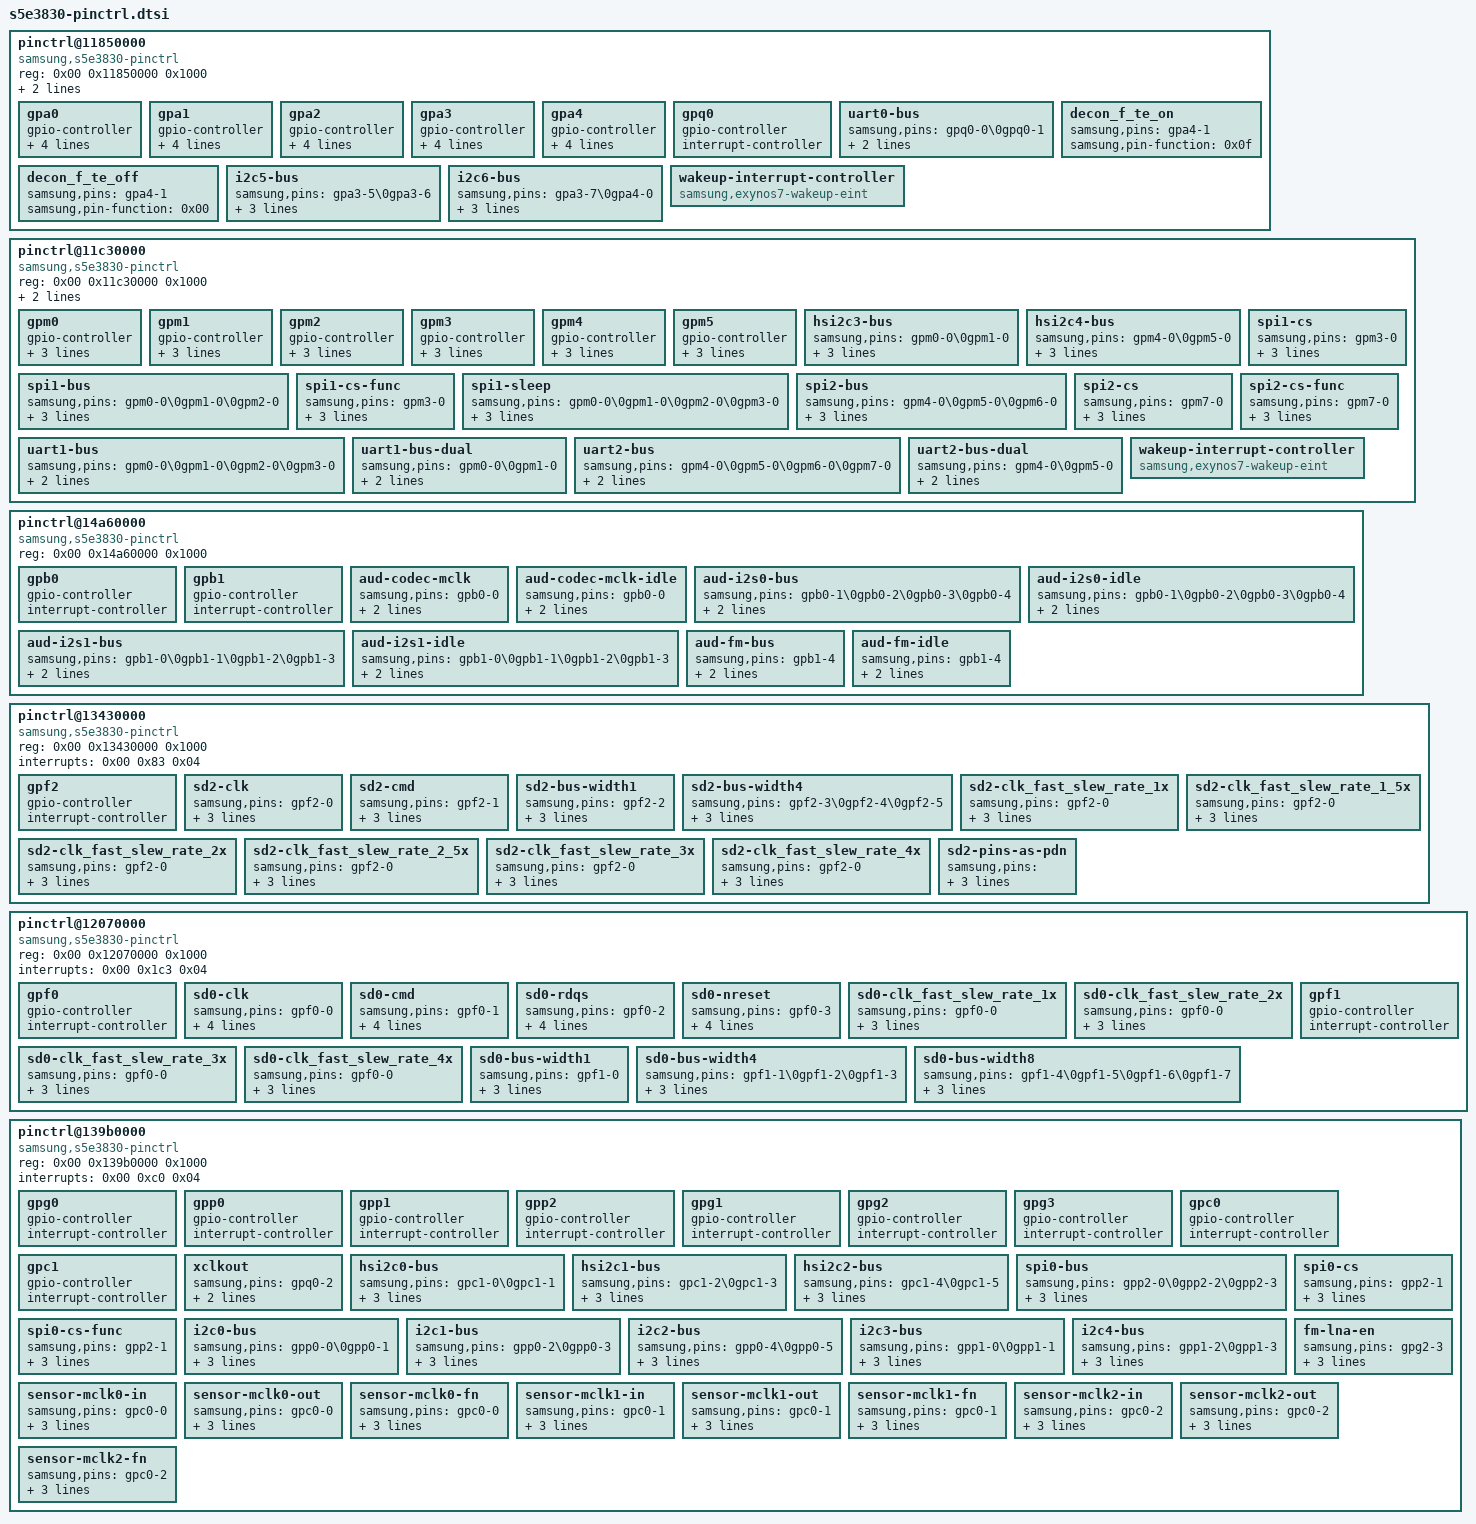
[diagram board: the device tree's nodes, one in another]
/* Samsung Exynos 850 (S5E3830) - pin controllers and board pin config */

	pinctrl@11850000 {
		compatible = "samsung,s5e3830-pinctrl";
		reg = <0x00 0x11850000 0x1000>;
		interrupts = <0x00 0x01 0x04 0x00 0x02 0x04 0x00 0x03 0x04 0x00 0x04 0x04 0x00 0x05 0x04 0x00 0x06 0x04 0x00 0x07 0x04 0x00 0x08 0x04 0x00 0x09 0x04 0x00 0x0a 0x04 0x00 0x0b 0x04 0x00 0x0c 0x04 0x00 0x0d 0x04 0x00 0x0e 0x04 0x00 0x0f 0x04 0x00 0x10 0x04 0x00 0x11 0x04 0x00 0x12 0x04 0x00 0x13 0x04 0x00 0x14 0x04 0x00 0x15 0x04 0x00 0x16 0x04 0x00 0x17 0x04 0x00 0x18 0x04 0x00 0x19 0x04 0x00 0x1a 0x04 0x00 0x1b 0x04 0x00 0x1c 0x04 0x00 0x1d 0x04 0x00 0x1e 0x04 0x00 0x1f 0x04 0x00 0x20 0x04>;
		phandle = <0xb8>;

		gpa0 {
			gpio-controller;
			#gpio-cells = <0x02>;
			interrupt-controller;
			#interrupt-cells = <0x03>;
			interrupt-parent = <0x01>;
			interrupts = <0x00 0x01 0x04 0x00 0x02 0x04 0x00 0x03 0x04 0x00 0x04 0x04 0x00 0x05 0x04 0x00 0x06 0x04 0x00 0x07 0x04 0x00 0x08 0x04>;
			phandle = <0xb9>;
		};

		gpa1 {
			gpio-controller;
			#gpio-cells = <0x02>;
			interrupt-controller;
			#interrupt-cells = <0x03>;
			interrupt-parent = <0x01>;
			interrupts = <0x00 0x09 0x04 0x00 0x0a 0x04 0x00 0x0b 0x04 0x00 0x0c 0x04 0x00 0x0d 0x04 0x00 0x0e 0x04 0x00 0x0f 0x04 0x00 0x10 0x04>;
			phandle = <0xba>;
		};

		gpa2 {
			gpio-controller;
			#gpio-cells = <0x02>;
			interrupt-controller;
			#interrupt-cells = <0x03>;
			interrupt-parent = <0x01>;
			interrupts = <0x00 0x11 0x04 0x00 0x12 0x04 0x00 0x13 0x04 0x00 0x14 0x04 0x00 0x15 0x04 0x00 0x16 0x04 0x00 0x17 0x04 0x00 0x18 0x04>;
			phandle = <0xbb>;
		};

		gpa3 {
			gpio-controller;
			#gpio-cells = <0x02>;
			interrupt-controller;
			#interrupt-cells = <0x03>;
			interrupt-parent = <0x01>;
			interrupts = <0x00 0x19 0x04 0x00 0x1a 0x04 0x00 0x1b 0x04 0x00 0x1c 0x04 0x00 0x1d 0x04 0x00 0x1e 0x04 0x00 0x1f 0x04 0x00 0x20 0x04>;
			phandle = <0x1b>;
		};

		gpa4 {
			gpio-controller;
			#gpio-cells = <0x02>;
			interrupt-controller;
			#interrupt-cells = <0x03>;
			interrupt-parent = <0x01>;
			interrupts = <0x00 0x21 0x04 0x00 0x22 0x04 0x00 0x23 0x04 0x00 0x24 0x04>;
			phandle = <0x1d>;
		};

		gpq0 {
			gpio-controller;
			#gpio-cells = <0x02>;
			interrupt-controller;
			#interrupt-cells = <0x02>;
			phandle = <0xbc>;
		};

		uart0-bus {
			samsung,pins = "gpq0-0\0gpq0-1";
			samsung,pin-function = <0x02>;
			samsung,pin-pud = <0x03>;
			phandle = <0x11>;
		};

		decon_f_te_on {
			samsung,pins = "gpa4-1";
			samsung,pin-function = <0x0f>;
			phandle = <0x73>;
		};

		decon_f_te_off {
			samsung,pins = "gpa4-1";
			samsung,pin-function = <0x00>;
			phandle = <0x74>;
		};

		i2c5-bus {
			samsung,pins = "gpa3-5\0gpa3-6";
			samsung,pin-function = <0x03>;
			samsung,pin-pud = <0x03>;
			samsung,pin-drv = <0x00>;
			phandle = <0x1a>;
		};

		i2c6-bus {
			samsung,pins = "gpa3-7\0gpa4-0";
			samsung,pin-function = <0x03>;
			samsung,pin-pud = <0x03>;
			samsung,pin-drv = <0x00>;
			phandle = <0x1c>;
		};

		wakeup-interrupt-controller {
			compatible = "samsung,exynos7-wakeup-eint";
		};
	};

	pinctrl@11c30000 {
		compatible = "samsung,s5e3830-pinctrl";
		reg = <0x00 0x11c30000 0x1000>;
		interrupts = <0x00 0x27 0x04 0x00 0x28 0x04 0x00 0x29 0x04 0x00 0x2a 0x04 0x00 0x2b 0x04 0x00 0x2c 0x04 0x00 0x2d 0x04 0x00 0x2e 0x04>;
		phandle = <0xbd>;

		gpm0 {
			gpio-controller;
			#gpio-cells = <0x02>;
			interrupt-controller;
			#interrupt-cells = <0x03>;
			interrupt-parent = <0x01>;
			interrupts = <0x00 0x27 0x04>;
			phandle = <0x08>;
		};

		gpm1 {
			gpio-controller;
			#gpio-cells = <0x02>;
			interrupt-controller;
			#interrupt-cells = <0x03>;
			interrupt-parent = <0x01>;
			interrupts = <0x00 0x28 0x04>;
			phandle = <0x09>;
		};

		gpm2 {
			gpio-controller;
			#gpio-cells = <0x02>;
			interrupt-controller;
			#interrupt-cells = <0x03>;
			interrupt-parent = <0x01>;
			interrupts = <0x00 0x29 0x04>;
			phandle = <0xbe>;
		};

		gpm3 {
			gpio-controller;
			#gpio-cells = <0x02>;
			interrupt-controller;
			#interrupt-cells = <0x03>;
			interrupt-parent = <0x01>;
			interrupts = <0x00 0x2a 0x04>;
			phandle = <0xbf>;
		};

		gpm4 {
			gpio-controller;
			#gpio-cells = <0x02>;
			interrupt-controller;
			#interrupt-cells = <0x03>;
			interrupt-parent = <0x01>;
			interrupts = <0x00 0x2b 0x04>;
			phandle = <0x0b>;
		};

		gpm5 {
			gpio-controller;
			#gpio-cells = <0x02>;
			interrupt-controller;
			#interrupt-cells = <0x03>;
			interrupt-parent = <0x01>;
			interrupts = <0x00 0x2c 0x04>;
			phandle = <0x0c>;
		};

		hsi2c3-bus {
			samsung,pins = "gpm0-0\0gpm1-0";
			samsung,pin-function = <0x02>;
			samsung,pin-pud = <0x03>;
			samsung,pin-drv = <0x00>;
			phandle = <0x07>;
		};

		hsi2c4-bus {
			samsung,pins = "gpm4-0\0gpm5-0";
			samsung,pin-function = <0x02>;
			samsung,pin-pud = <0x03>;
			samsung,pin-drv = <0x00>;
			phandle = <0x0a>;
		};

		spi1-bus {
			samsung,pins = "gpm0-0\0gpm1-0\0gpm2-0";
			samsung,pin-function = <0x02>;
			samsung,pin-pud = <0x00>;
			samsung,pin-drv = <0x00>;
			phandle = <0x0f>;
		};

		spi1-cs {
			samsung,pins = "gpm3-0";
			samsung,pin-function = <0x01>;
			samsung,pin-pud = <0x00>;
			samsung,pin-drv = <0x00>;
			phandle = <0xc0>;
		};

		spi1-cs-func {
			samsung,pins = "gpm3-0";
			samsung,pin-function = <0x02>;
			samsung,pin-pud = <0x00>;
			samsung,pin-drv = <0x00>;
			phandle = <0xc1>;
		};

		spi1-sleep {
			samsung,pins = "gpm0-0\0gpm1-0\0gpm2-0\0gpm3-0";
			samsung,pin-function = <0x00>;
			samsung,pin-pud = <0x01>;
			samsung,pin-drv = <0x00>;
			phandle = <0xc2>;
		};

		spi2-bus {
			samsung,pins = "gpm4-0\0gpm5-0\0gpm6-0";
			samsung,pin-function = <0x02>;
			samsung,pin-pud = <0x00>;
			samsung,pin-drv = <0x00>;
			phandle = <0x10>;
		};

		spi2-cs {
			samsung,pins = "gpm7-0";
			samsung,pin-function = <0x01>;
			samsung,pin-pud = <0x00>;
			samsung,pin-drv = <0x00>;
			phandle = <0xc3>;
		};

		spi2-cs-func {
			samsung,pins = "gpm7-0";
			samsung,pin-function = <0x02>;
			samsung,pin-pud = <0x00>;
			samsung,pin-drv = <0x00>;
			phandle = <0xc4>;
		};

		uart1-bus {
			samsung,pins = "gpm0-0\0gpm1-0\0gpm2-0\0gpm3-0";
			samsung,pin-function = <0x02>;
			samsung,pin-pud = <0x00>;
			phandle = <0xc5>;
		};

		uart1-bus-dual {
			samsung,pins = "gpm0-0\0gpm1-0";
			samsung,pin-function = <0x02>;
			samsung,pin-pud = <0x00>;
			phandle = <0xc6>;
		};

		uart2-bus {
			samsung,pins = "gpm4-0\0gpm5-0\0gpm6-0\0gpm7-0";
			samsung,pin-function = <0x02>;
			samsung,pin-pud = <0x00>;
			phandle = <0xc7>;
		};

		uart2-bus-dual {
			samsung,pins = "gpm4-0\0gpm5-0";
			samsung,pin-function = <0x02>;
			samsung,pin-pud = <0x00>;
			phandle = <0xc8>;
		};

		wakeup-interrupt-controller {
			compatible = "samsung,exynos7-wakeup-eint";
		};
	};

	pinctrl@14a60000 {
		compatible = "samsung,s5e3830-pinctrl";
		reg = <0x00 0x14a60000 0x1000>;
		phandle = <0xc9>;

		gpb0 {
			gpio-controller;
			#gpio-cells = <0x02>;
			interrupt-controller;
			#interrupt-cells = <0x02>;
			phandle = <0xca>;
		};

		gpb1 {
			gpio-controller;
			#gpio-cells = <0x02>;
			interrupt-controller;
			#interrupt-cells = <0x02>;
			phandle = <0xcb>;
		};

		aud-codec-mclk {
			samsung,pins = "gpb0-0";
			samsung,pin-function = <0x02>;
			samsung,pin-pud = <0x01>;
			phandle = <0x7d>;
		};

		aud-codec-mclk-idle {
			samsung,pins = "gpb0-0";
			samsung,pin-function = <0x00>;
			samsung,pin-pud = <0x01>;
			phandle = <0x7f>;
		};

		aud-i2s0-bus {
			samsung,pins = "gpb0-1\0gpb0-2\0gpb0-3\0gpb0-4";
			samsung,pin-function = <0x02>;
			samsung,pin-pud = <0x01>;
			phandle = <0x7c>;
		};

		aud-i2s0-idle {
			samsung,pins = "gpb0-1\0gpb0-2\0gpb0-3\0gpb0-4";
			samsung,pin-function = <0x00>;
			samsung,pin-pud = <0x01>;
			phandle = <0x7e>;
		};

		aud-i2s1-bus {
			samsung,pins = "gpb1-0\0gpb1-1\0gpb1-2\0gpb1-3";
			samsung,pin-function = <0x02>;
			samsung,pin-pud = <0x01>;
			phandle = <0x80>;
		};

		aud-i2s1-idle {
			samsung,pins = "gpb1-0\0gpb1-1\0gpb1-2\0gpb1-3";
			samsung,pin-function = <0x00>;
			samsung,pin-pud = <0x01>;
			phandle = <0x81>;
		};

		aud-fm-bus {
			samsung,pins = "gpb1-4";
			samsung,pin-function = <0x02>;
			samsung,pin-pud = <0x01>;
			phandle = <0x97>;
		};

		aud-fm-idle {
			samsung,pins = "gpb1-4";
			samsung,pin-function = <0x00>;
			samsung,pin-pud = <0x01>;
			phandle = <0x98>;
		};
	};

	pinctrl@13430000 {
		compatible = "samsung,s5e3830-pinctrl";
		reg = <0x00 0x13430000 0x1000>;
		interrupts = <0x00 0x83 0x04>;
		phandle = <0xcc>;

		gpf2 {
			gpio-controller;
			#gpio-cells = <0x02>;
			interrupt-controller;
			#interrupt-cells = <0x02>;
			phandle = <0xcd>;
		};

		sd2-clk {
			samsung,pins = "gpf2-0";
			samsung,pin-function = <0x02>;
			samsung,pin-pud = <0x00>;
			samsung,pin-drv = <0x02>;
			phandle = <0x4a>;
		};

		sd2-cmd {
			samsung,pins = "gpf2-1";
			samsung,pin-function = <0x02>;
			samsung,pin-pud = <0x03>;
			samsung,pin-drv = <0x02>;
			phandle = <0x4b>;
		};

		sd2-bus-width1 {
			samsung,pins = "gpf2-2";
			samsung,pin-function = <0x02>;
			samsung,pin-pud = <0x03>;
			samsung,pin-drv = <0x02>;
			phandle = <0x4c>;
		};

		sd2-bus-width4 {
			samsung,pins = "gpf2-3\0gpf2-4\0gpf2-5";
			samsung,pin-function = <0x02>;
			samsung,pin-pud = <0x03>;
			samsung,pin-drv = <0x02>;
			phandle = <0x4d>;
		};

		sd2-clk_fast_slew_rate_1x {
			samsung,pins = "gpf2-0";
			samsung,pin-function = <0x02>;
			samsung,pin-pud = <0x00>;
			samsung,pin-drv = <0x00>;
			phandle = <0x43>;
		};

		sd2-clk_fast_slew_rate_1_5x {
			samsung,pins = "gpf2-0";
			samsung,pin-function = <0x02>;
			samsung,pin-pud = <0x00>;
			samsung,pin-drv = <0x01>;
			phandle = <0x44>;
		};

		sd2-clk_fast_slew_rate_2x {
			samsung,pins = "gpf2-0";
			samsung,pin-function = <0x02>;
			samsung,pin-pud = <0x00>;
			samsung,pin-drv = <0x02>;
			phandle = <0x45>;
		};

		sd2-clk_fast_slew_rate_2_5x {
			samsung,pins = "gpf2-0";
			samsung,pin-function = <0x02>;
			samsung,pin-pud = <0x00>;
			samsung,pin-drv = <0x03>;
			phandle = <0x46>;
		};

		sd2-clk_fast_slew_rate_3x {
			samsung,pins = "gpf2-0";
			samsung,pin-function = <0x02>;
			samsung,pin-pud = <0x00>;
			samsung,pin-drv = <0x04>;
			phandle = <0x47>;
		};

		sd2-clk_fast_slew_rate_4x {
			samsung,pins = "gpf2-0";
			samsung,pin-function = <0x02>;
			samsung,pin-pud = <0x00>;
			samsung,pin-drv = <0x05>;
			phandle = <0x48>;
		};

		sd2-pins-as-pdn {
			samsung,pins = "gpf2-0\0gpf2-1\0gpf2-2\0gpf2-3\0gpf2-4\0gpf2-5";
			samsung,pin-function = <0x00>;
			samsung,pin-pud = <0x02>;
			phandle = <0x49>;
		};
	};

	pinctrl@12070000 {
		compatible = "samsung,s5e3830-pinctrl";
		reg = <0x00 0x12070000 0x1000>;
		interrupts = <0x00 0x1c3 0x04>;
		phandle = <0xce>;

		gpf0 {
			gpio-controller;
			#gpio-cells = <0x02>;
			interrupt-controller;
			#interrupt-cells = <0x02>;
			phandle = <0xcf>;
		};

		sd0-clk {
			samsung,pins = "gpf0-0";
			samsung,pin-function = <0x02>;
			samsung,pin-pud = <0x00>;
			samsung,pin-drv = <0x03>;
			samsung,pin-pud-pdn = <0x00>;
			phandle = <0x37>;
		};

		sd0-cmd {
			samsung,pins = "gpf0-1";
			samsung,pin-function = <0x02>;
			samsung,pin-pud = <0x03>;
			samsung,pin-drv = <0x03>;
			samsung,pin-pud-pdn = <0x03>;
			phandle = <0x38>;
		};

		sd0-rdqs {
			samsung,pins = "gpf0-2";
			samsung,pin-function = <0x02>;
			samsung,pin-pud = <0x01>;
			samsung,pin-drv = <0x03>;
			samsung,pin-pud-pdn = <0x01>;
			phandle = <0x39>;
		};

		sd0-nreset {
			samsung,pins = "gpf0-3";
			samsung,pin-function = <0x02>;
			samsung,pin-pud = <0x03>;
			samsung,pin-drv = <0x03>;
			samsung,pin-pud-pdn = <0x03>;
			phandle = <0x3a>;
		};

		sd0-clk_fast_slew_rate_1x {
			samsung,pins = "gpf0-0";
			samsung,pin-function = <0x02>;
			samsung,pin-pud = <0x00>;
			samsung,pin-drv = <0x01>;
			phandle = <0x3e>;
		};

		sd0-clk_fast_slew_rate_2x {
			samsung,pins = "gpf0-0";
			samsung,pin-function = <0x02>;
			samsung,pin-pud = <0x00>;
			samsung,pin-drv = <0x02>;
			phandle = <0x3f>;
		};

		sd0-clk_fast_slew_rate_3x {
			samsung,pins = "gpf0-0";
			samsung,pin-function = <0x02>;
			samsung,pin-pud = <0x00>;
			samsung,pin-drv = <0x02>;
			phandle = <0x40>;
		};

		sd0-clk_fast_slew_rate_4x {
			samsung,pins = "gpf0-0";
			samsung,pin-function = <0x02>;
			samsung,pin-pud = <0x00>;
			samsung,pin-drv = <0x03>;
			phandle = <0x41>;
		};

		gpf1 {
			gpio-controller;
			#gpio-cells = <0x02>;
			interrupt-controller;
			#interrupt-cells = <0x02>;
			phandle = <0xd0>;
		};

		sd0-bus-width1 {
			samsung,pins = "gpf1-0";
			samsung,pin-function = <0x02>;
			samsung,pin-pud = <0x03>;
			samsung,pin-drv = <0x03>;
			phandle = <0x3b>;
		};

		sd0-bus-width4 {
			samsung,pins = "gpf1-1\0gpf1-2\0gpf1-3";
			samsung,pin-function = <0x02>;
			samsung,pin-pud = <0x03>;
			samsung,pin-drv = <0x03>;
			phandle = <0x3c>;
		};

		sd0-bus-width8 {
			samsung,pins = "gpf1-4\0gpf1-5\0gpf1-6\0gpf1-7";
			samsung,pin-function = <0x02>;
			samsung,pin-pud = <0x03>;
			samsung,pin-drv = <0x03>;
			phandle = <0x3d>;
		};
	};

	pinctrl@139b0000 {
		compatible = "samsung,s5e3830-pinctrl";
		reg = <0x00 0x139b0000 0x1000>;
		interrupts = <0x00 0xc0 0x04>;
		phandle = <0xd1>;

		gpg0 {
			gpio-controller;
			#gpio-cells = <0x02>;
			interrupt-controller;
			#interrupt-cells = <0x02>;
			phandle = <0xd2>;
		};

		gpp0 {
			gpio-controller;
			#gpio-cells = <0x02>;
			interrupt-controller;
			#interrupt-cells = <0x02>;
			phandle = <0x14>;
		};

		gpp1 {
			gpio-controller;
			#gpio-cells = <0x02>;
			interrupt-controller;
			#interrupt-cells = <0x02>;
			phandle = <0x18>;
		};

		gpp2 {
			gpio-controller;
			#gpio-cells = <0x02>;
			interrupt-controller;
			#interrupt-cells = <0x02>;
			phandle = <0xd3>;
		};

		gpg1 {
			gpio-controller;
			#gpio-cells = <0x02>;
			interrupt-controller;
			#interrupt-cells = <0x02>;
			phandle = <0xd4>;
		};

		gpg2 {
			gpio-controller;
			#gpio-cells = <0x02>;
			interrupt-controller;
			#interrupt-cells = <0x02>;
			phandle = <0x96>;
		};

		gpg3 {
			gpio-controller;
			#gpio-cells = <0x02>;
			interrupt-controller;
			#interrupt-cells = <0x02>;
			phandle = <0xd5>;
		};

		gpc0 {
			gpio-controller;
			#gpio-cells = <0x02>;
			interrupt-controller;
			#interrupt-cells = <0x02>;
			phandle = <0xd6>;
		};

		gpc1 {
			gpio-controller;
			#gpio-cells = <0x02>;
			interrupt-controller;
			#interrupt-cells = <0x02>;
			phandle = <0x04>;
		};

		xclkout {
			samsung,pins = "gpq0-2";
			samsung,pin-function = <0x02>;
			samsung,pin-pud = <0x00>;
			phandle = <0xd7>;
		};

		hsi2c0-bus {
			samsung,pins = "gpc1-0\0gpc1-1";
			samsung,pin-function = <0x02>;
			samsung,pin-pud = <0x03>;
			samsung,pin-drv = <0x00>;
			phandle = <0x02>;
		};

		hsi2c1-bus {
			samsung,pins = "gpc1-2\0gpc1-3";
			samsung,pin-function = <0x02>;
			samsung,pin-pud = <0x03>;
			samsung,pin-drv = <0x00>;
			phandle = <0x05>;
		};

		hsi2c2-bus {
			samsung,pins = "gpc1-4\0gpc1-5";
			samsung,pin-function = <0x02>;
			samsung,pin-pud = <0x03>;
			samsung,pin-drv = <0x00>;
			phandle = <0x06>;
		};

		spi0-bus {
			samsung,pins = "gpp2-0\0gpp2-2\0gpp2-3";
			samsung,pin-function = <0x02>;
			samsung,pin-pud = <0x00>;
			samsung,pin-drv = <0x00>;
			phandle = <0x0e>;
		};

		spi0-cs {
			samsung,pins = "gpp2-1";
			samsung,pin-function = <0x01>;
			samsung,pin-pud = <0x00>;
			samsung,pin-drv = <0x00>;
			phandle = <0xd8>;
		};

		spi0-cs-func {
			samsung,pins = "gpp2-1";
			samsung,pin-function = <0x02>;
			samsung,pin-pud = <0x00>;
			samsung,pin-drv = <0x00>;
			phandle = <0xd9>;
		};

		i2c0-bus {
			samsung,pins = "gpp0-0\0gpp0-1";
			samsung,pin-function = <0x02>;
			samsung,pin-pud = <0x00>;
			samsung,pin-drv = <0x00>;
			phandle = <0x13>;
		};

		i2c1-bus {
			samsung,pins = "gpp0-2\0gpp0-3";
			samsung,pin-function = <0x02>;
			samsung,pin-pud = <0x03>;
			samsung,pin-drv = <0x00>;
			phandle = <0x15>;
		};

		i2c2-bus {
			samsung,pins = "gpp0-4\0gpp0-5";
			samsung,pin-function = <0x02>;
			samsung,pin-pud = <0x03>;
			samsung,pin-drv = <0x00>;
			phandle = <0x16>;
		};

		i2c3-bus {
			samsung,pins = "gpp1-0\0gpp1-1";
			samsung,pin-function = <0x02>;
			samsung,pin-pud = <0x03>;
			samsung,pin-drv = <0x00>;
			phandle = <0x17>;
		};

		i2c4-bus {
			samsung,pins = "gpp1-2\0gpp1-3";
			samsung,pin-function = <0x02>;
			samsung,pin-pud = <0x03>;
			samsung,pin-drv = <0x00>;
			phandle = <0x19>;
		};

		fm-lna-en {
			samsung,pins = "gpg2-3";
			samsung,pin-function = <0x01>;
			samsung,pin-pud = <0x00>;
			samsung,pin-val = <0x00>;
			phandle = <0xda>;
		};

		sensor-mclk0-in {
			samsung,pins = "gpc0-0";
			samsung,pin-function = <0x00>;
			samsung,pin-pud = <0x00>;
			samsung,pin-drv = <0x02>;
			phandle = <0xdb>;
		};

		sensor-mclk0-out {
			samsung,pins = "gpc0-0";
			samsung,pin-function = <0x01>;
			samsung,pin-pud = <0x01>;
			samsung,pin-drv = <0x02>;
			phandle = <0xdc>;
		};

		sensor-mclk0-fn {
			samsung,pins = "gpc0-0";
			samsung,pin-function = <0x02>;
			samsung,pin-pud = <0x00>;
			samsung,pin-drv = <0x02>;
			phandle = <0xdd>;
		};

		sensor-mclk1-in {
			samsung,pins = "gpc0-1";
			samsung,pin-function = <0x00>;
			samsung,pin-pud = <0x00>;
			samsung,pin-drv = <0x02>;
			phandle = <0xde>;
		};

		sensor-mclk1-out {
			samsung,pins = "gpc0-1";
			samsung,pin-function = <0x01>;
			samsung,pin-pud = <0x01>;
			samsung,pin-drv = <0x02>;
			phandle = <0xdf>;
		};

		sensor-mclk1-fn {
			samsung,pins = "gpc0-1";
			samsung,pin-function = <0x02>;
			samsung,pin-pud = <0x00>;
			samsung,pin-drv = <0x02>;
			phandle = <0xe0>;
		};

		sensor-mclk2-in {
			samsung,pins = "gpc0-2";
			samsung,pin-function = <0x00>;
			samsung,pin-pud = <0x00>;
			samsung,pin-drv = <0x02>;
			phandle = <0xe1>;
		};

		sensor-mclk2-out {
			samsung,pins = "gpc0-2";
			samsung,pin-function = <0x01>;
			samsung,pin-pud = <0x01>;
			samsung,pin-drv = <0x02>;
			phandle = <0xe2>;
		};

		sensor-mclk2-fn {
			samsung,pins = "gpc0-2";
			samsung,pin-function = <0x02>;
			samsung,pin-pud = <0x00>;
			samsung,pin-drv = <0x02>;
			phandle = <0xe3>;
		};
	};
